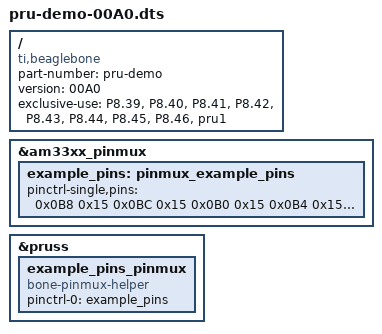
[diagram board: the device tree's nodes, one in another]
/* Set bits 0-7 of PRU1's R30 to outputs */

/dts-v1/;
/plugin/;

/{
    compatible = "ti,beaglebone", "ti,beaglebone-black", "ti,beaglebone-green";
    part-number = "pru-demo";
    version = "00A0";
	
    exclusive-use = 
        "P8.39",
        "P8.40",
        "P8.41",
        "P8.42",
        "P8.43",
        "P8.44",
        "P8.45",
        "P8.46",
        "pru1";

    fragment@0 {  
        target = <&am33xx_pinmux>;  
        __overlay__ {  
            example_pins: pinmux_example_pins {  
                pinctrl-single,pins = <  
                    0x0B8 0x15
                    0x0BC 0x15
                    0x0B0 0x15
                    0x0B4 0x15
                    0x0A8 0x15
                    0x0AC 0x15
                    0x0A0 0x15
                    0x0A4 0x15
                >;  
            };
        };
    };  

    fragment@1 {
        target = <&pruss>;
        __overlay__ {
            example_pins_pinmux {
                compatible = "bone-pinmux-helper";
                status = "okay";
                pinctrl-names = "default";
                pinctrl-0 = <&example_pins>;
            };
        };
    };
};

